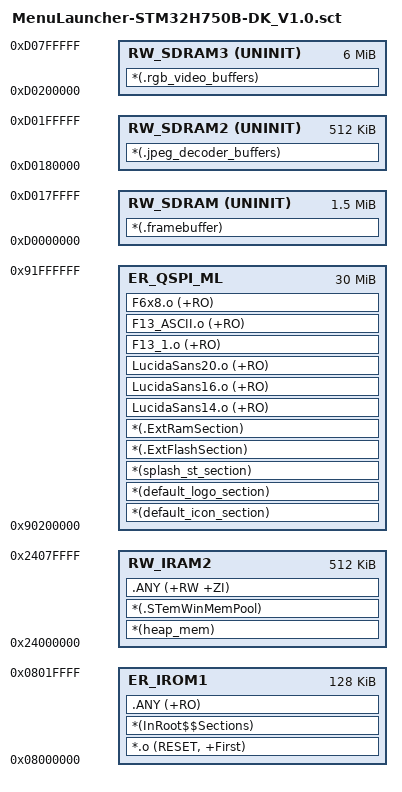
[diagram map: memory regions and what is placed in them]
; *************************************************************
; *** Scatter-Loading Description File generated by uVision ***
; *************************************************************

LR_IROM1 0x08000000 0x00020000  {    ; load region size_region
  ER_IROM1 0x08000000 0x00020000  {  ; load address = execution address
		*.o (RESET, +First)
		*(InRoot$$Sections)
		.ANY (+RO)
  }
  RW_IRAM2 0x24000000 0x00080000  {
  		*(heap_mem)
		*(.STemWinMemPool)	
         .ANY (+RW +ZI)
  }
}
LR_SDRAM 0xD0000000   0x800000{
	RW_SDRAM 0xD0000000  UNINIT 0x180000{
		*(.framebuffer)		
			}
	RW_SDRAM2 0xD0180000  UNINIT 0x80000{
		*(.jpeg_decoder_buffers)
   }
	RW_SDRAM3 0xD0200000  UNINIT 0x600000{
		*(.rgb_video_buffers)			
	}
	}
LR_QSPI_ML  0x90200000 0x1E00000  { 
	ER_QSPI_ML  0x90200000 0x1E00000  { 
		*(default_icon_section)
		*(default_logo_section)
		*(splash_st_section)
		*(.ExtFlashSection)
		*(.ExtRamSection)
		LucidaSans14.o (+RO)
		LucidaSans16.o (+RO)
		LucidaSans20.o (+RO)
		F13_1.o  (+RO)
		F13_ASCII.o (+RO)
		F6x8.o  (+RO)
}
}

